# StarFive VisionFive 2 v1.3b register map
File version: 0.1
Registers are 32-bit, read-write, no defined reset value unless marked. A register's access mark holds for its fields unless they carry their own. Offsets are from the block's base; [hi:lo] are bit positions; {n}, {i} and the like mark numbered series; 'fields as' and 'values as' point back to an identical list.

## starfive_jh7110_syscrg_0 — From starfive,jh7110-syscrg, peripheral generator
Base 0x13020000
0x00 clk_cpu_root — Clock CPU Root
  [29:24] clk_mux_sel — Clock multiplexing selector: clk_osc, clk_pll0
0x04 clk_cpu_core — Clock CPU Core
  [23:0] clk_divcfg — Clock divider coefficient: Max=7, Default=1, Min=1, Typical=1
0x08 clk_cpu_bus — Clock CPU Bus
  [23:0] clk_divcfg — Clock divider coefficient: Max=2, Default=2, Min=2, Typical=2
0x0C clk_gpu_root — Clock GPU Root
  [29:24] clk_mux_sel — Clock multiplexing selector: clk_pll2, clk_pll1
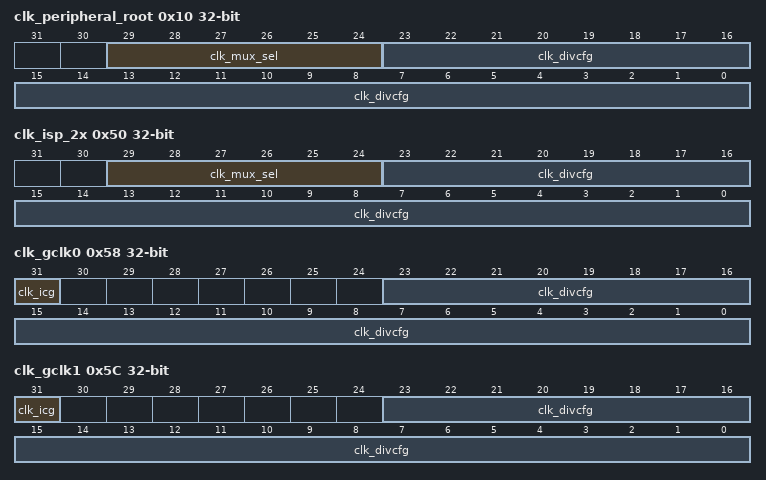
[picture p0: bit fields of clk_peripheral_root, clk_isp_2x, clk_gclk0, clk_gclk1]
0x10 clk_peripheral_root — Clock Peripheral Root
  [29:24] clk_mux_sel — Clock multiplexing selector: clk_pll0, clk_pll2
  [23:0] clk_divcfg — Clock divider coefficient: Max=2, Default=2, Min=2, Typical=2
0x14 clk_bus_root — Clock Bus Root
  [29:24] clk_mux_sel — Clock multiplexing selector: clk_osc, clk_pll2
0x18 clk_nocstg_bus — Clock NOCSTG Bus
  [23:0] clk_divcfg — Clock divider coefficient: Max=3, Default=3, Min=3, Typical=3
0x1C clk_axi_cfg0 — Clock AXI Configuration 0
  fields as clk_nocstg_bus
0x20 clk_stg_axiahb — Clock STG AXI AHB
  fields as clk_cpu_bus
0x24 clk_ahb0 — Clock AHB 0
  [31] clk_icg — 1: Clock enable, 0: Clock disable
0x28 clk_ahb1 — Clock AHB 1
  [31] clk_icg — 1: Clock enable, 0: Clock disable
0x2C clk_apb_bus — Clock APB Bus
  [23:0] clk_divcfg — Clock divider coefficient: Max=8, Default=4, Min=4, Typical=4
0x30 clk_apb0 — Clock APB 0
  [31] clk_icg — 1: Clock enable, 0: Clock disable
{0x34+4i} clk_pll{i}_div2 (i=0..2) — Clock PLL {i} Divider 2
  fields as clk_cpu_bus
0x40 clk_audio_root — Clock Audio Root
  [23:0] clk_divcfg — Clock divider coefficient: Max=8, Default=2, Min=2, Typical=2
0x44 clk_mclk_inner — Clock MCLK Inner
  [23:0] clk_divcfg — Clock divider coefficient: Max=64, Default=12, Min=12, Typical=12
0x48 clk_mclk — Clock MCLK
  [29:24] clk_mux_sel — Clock multiplexing selector: clk_mclk_inner, clk_mclk_ext
0x4C clk_mclk_out — Clock MCLK Out
  [31] clk_icg — 1: Clock enable, 0: Clock disable
0x50 clk_isp_2x — Clock ISP 2x
  [29:24] clk_mux_sel — Clock multiplexing selector: clk_pll2, clk_pll1
  [23:0] clk_divcfg — Clock divider coefficient: Max=8, Default=2, Min=2, Typical=2
0x54 clk_isp_axi — Clock ISP AXI
  [23:0] clk_divcfg — Clock divider coefficient: Max=4, Default=2, Min=2, Typical=2
0x58 clk_gclk0 — Clock GCLK 0
  [31] clk_icg — 1: Clock enable, 0: Clock disable
  [23:0] clk_divcfg — Clock divider coefficient: Max=62, Default=20, Min=16, Typical=20
0x5C clk_gclk1 — Clock GCLK 1
  [31] clk_icg — 1: Clock enable, 0: Clock disable
  [23:0] clk_divcfg — Clock divider coefficient: Max=62, Default=16, Min=16, Typical=16
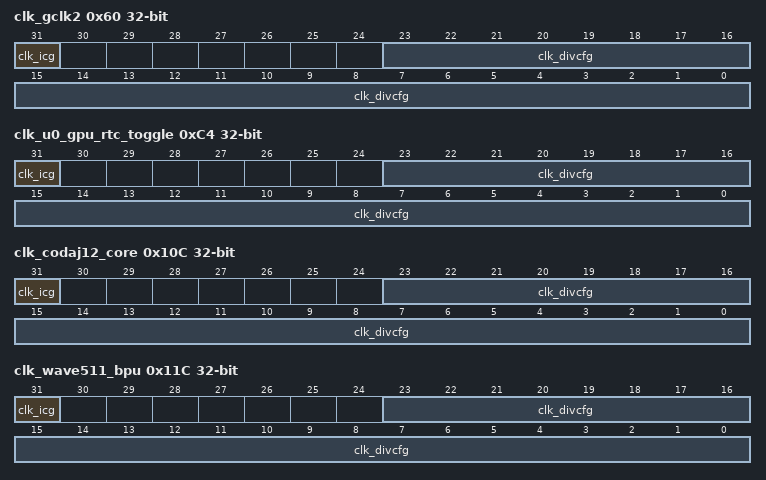
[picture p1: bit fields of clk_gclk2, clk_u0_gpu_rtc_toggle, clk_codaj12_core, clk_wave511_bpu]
0x60 clk_gclk2 — Clock GCLK 2
  [31] clk_icg — 1: Clock enable, 0: Clock disable
  [23:0] clk_divcfg — Clock divider coefficient: Max=62, Default=12, Min=12, Typical=12
{0x64+4i} clk_u7mc_core{i} (i=0..4) — U7MC Core Clock {i}
  [31] clk_icg — 1: Clock enable, 0: Clock disable
0x78 clk_u7mc_debug — U7MC Debug Clock
  [31] clk_icg — 1: Clock enable, 0: Clock disable
0x7C u7mc_rtc_toggle
  [23:0] clk_divcfg — Clock divider coefficient: Max=6, Default=6, Min=6, Typical=6
{0x80+4i} clk_u7mc_trace{i} (i=0..4) — U7MC Trace Clock {i}
  [31] clk_icg — 1: Clock enable, 0: Clock disable
0x94 clk_u7mc_trace_com — U7MC Trace Clock COM
  [31] clk_icg — 1: Clock enable, 0: Clock disable
0x98 clk_u0_sft7110_noc_bus_clk_cpu_axi
  [31] clk_icg — 1: Clock enable, 0: Clock disable
0x9C clk_u0_sft7110_noc_bus_clk_axicfg0_axi
  [31] clk_icg — 1: Clock enable, 0: Clock disable
0xA0 clk_osc_div2
  fields as clk_cpu_bus
0xA4 clk_pll1_div4
  fields as clk_cpu_bus
0xA8 clk_pll1_div8
  fields as clk_cpu_bus
0xAC clk_ddr_bus
  [29:24] clk_mux_sel — Clock multiplexing selector: clk_osc_div2, clk_pll1_div4, clk_pll1_div8
0xB0 clk_u0_ddr_sft7110_clk_axi — clk_u0_ddr_sfft7110_clk_axi
  [31] clk_icg — 1: Clock enable, 0: Clock disable
0xB4 clk_gpu_core
  [23:0] clk_divcfg — Clock divider coefficient: Max=7, Default=3, Min=3, Typical=3
0xB8 clk_u0_img_gpu_core_clk
  [31] clk_icg — 1: Clock enable, 0: Clock disable
0xBC clk_u0_img_gpu_sys_clk
  [31] clk_icg — 1: Clock enable, 0: Clock disable
0xC0 clk_u0_img_gpu_clk_apb
  [31] clk_icg — 1: Clock enable, 0: Clock disable
0xC4 clk_u0_gpu_rtc_toggle
  [31] clk_icg — 1: Clock enable, 0: Clock disable
  [23:0] clk_divcfg — Clock divider coefficient: Max=12, Default=12, Min=12, Typical=12
0xC8 clk_u0_sft7110_noc_bus_clk_gpu_axi
  [31] clk_icg — 1: Clock enable, 0: Clock disable
0xCC clk_u0_dom_isp_top_clk_dom_isp_top_clk_ispcore_2x
  [31] clk_icg — 1: Clock enable, 0: Clock disable
0xD0 clk_u0_dom_isp_top_clk_dom_isp_top_clk_isp_axi
  [31] clk_icg — 1: Clock enable, 0: Clock disable
0xD4 clk_u0_sft7110_noc_bux_clk_isp_axi
  [31] clk_icg — 1: Clock enable, 0: Clock disable
0xD8 clk_hifi4_core
  [23:0] clk_divcfg — Clock divider coefficient: Max=15, Default=3, Min=3, Typical=3
0xDC clk_hifi4_axi
  fields as clk_cpu_bus
0xE0 clk_u0_axi_cfg1_dec_clk_main
  [31] clk_icg — 1: Clock enable, 0: Clock disable
0xE4 clk_u0_axi_cfg1_dec_clk_ahb
  [31] clk_icg — 1: Clock enable, 0: Clock disable
0xE8 clk_u0_dom_vout_top_clk_dom_vout_top_clk_vout_src
  [31] clk_icg — 1: Clock enable, 0: Clock disable
0xEC clk_vout_axi_divcfg — Clock Video Output AXI DIVCFG
  [23:0] clk_divcfg — Clock divider coefficient: Max=7, Default=2, Min=2, Typical=2
0xF0 clk_noc_display_axi — Clock NOC Display AXI
  [31] clk_icg — 1: Clock enable, 0: Clock disable
0xF4 clk_vout_ahb — Clock Video Output AHB
  [31] clk_icg — 1: Clock enable, 0: Clock disable
0xF8 clk_vout_axi_icg — Clock Video Output AXI ICG
  [31] clk_icg — 1: Clock enable, 0: Clock disable
0xFC clk_vout_hdmi_tx0_mclk — Clock Video Output HDMI TX0 MCLK
  [31] clk_icg — 1: Clock enable, 0: Clock disable
0x100 clk_vout_mipi_phy — Clock Video Output MIPI PHY Reference
  fields as clk_cpu_bus
0x104 clk_jpeg_codec_axi — Clock JPEG Codec AXI
  [23:0] clk_divcfg — Clock divider coefficient: Max=16, Default=6, Min=6, Typical=6
0x108 clk_codaj12_axi — CODAJ12 Clock AXI
  [31] clk_icg — 1: Clock enable, 0: Clock disable
0x10C clk_codaj12_core — CODAJ12 Clock Core
  [31] clk_icg — 1: Clock enable, 0: Clock disable
  [23:0] clk_divcfg — Clock divider coefficient: Max=16, Default=6, Min=6, Typical=6
0x110 clk_codaj12_apb — CODAJ12 Clock APB
  [31] clk_icg — 1: Clock enable, 0: Clock disable
0x114 clk_vdec_axi — Clock Video Decoder AXI
  fields as clk_gpu_core
0x118 clk_wave511_axi — Clock WAVE511 AXI
  [31] clk_icg — 1: Clock enable, 0: Clock disable
0x11C clk_wave511_bpu — Clock WAVE511 BPU
  [31] clk_icg — 1: Clock enable, 0: Clock disable
  [23:0] clk_divcfg — Clock divider coefficient: Max=7, Default=3, Min=3, Typical=3
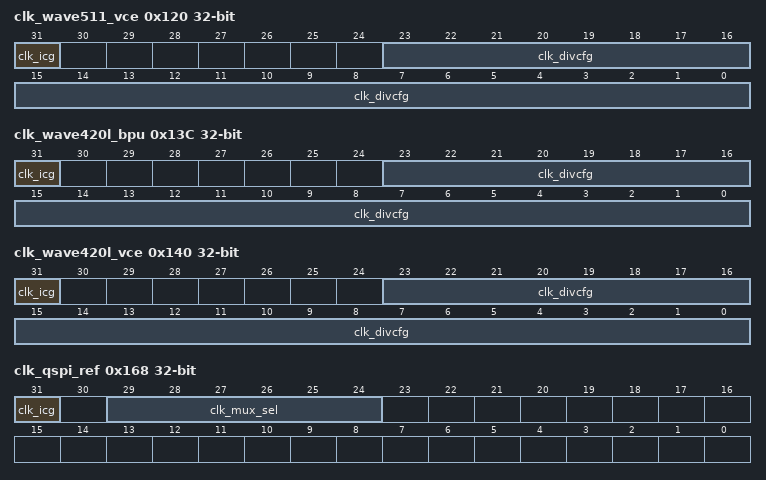
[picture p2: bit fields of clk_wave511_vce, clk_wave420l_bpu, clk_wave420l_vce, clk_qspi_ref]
0x120 clk_wave511_vce — Clock WAVE511 VCE
  [31] clk_icg — 1: Clock enable, 0: Clock disable
  [23:0] clk_divcfg — Clock divider coefficient: Max=7, Default=2, Min=3, Typical=2
0x124 clk_wave511_apb — Clock WAVE511 APB
  [31] clk_icg — 1: Clock enable, 0: Clock disable
0x128 clk_wave511_jpg_arb — Clock WAVE511 JPG ARB
  [31] clk_icg — 1: Clock enable, 0: Clock disable
0x12C clk_wave511_jpg_main — Clock WAVE511 JPG Main
  [31] clk_icg — 1: Clock enable, 0: Clock disable
0x130 clk_noc_vdec_axi — Clock NOC Video Decoder AXI
  [31] clk_icg — 1: Clock enable, 0: Clock disable
0x134 clk_venc_axi — Clock Video Encoder AXI
  [23:0] clk_divcfg — Clock divider coefficient: Max=15, Default=5, Min=5, Typical=5
0x138 clk_wave420l_axi — Clock WAVE420L AXI
  [31] clk_icg — 1: Clock enable, 0: Clock disable
0x13C clk_wave420l_bpu — Clock WAVE420L BPU
  [31] clk_icg — 1: Clock enable, 0: Clock disable
  [23:0] clk_divcfg — Clock divider coefficient: Max=15, Default=5, Min=5, Typical=5
0x140 clk_wave420l_vce — Clock WAVE420L VCE
  fields as clk_wave420l_bpu
0x144 clk_wave420l_apb — Clock WAVE420L APB
  [31] clk_icg — 1: Clock enable, 0: Clock disable
0x148 clk_noc_venc_axi — Clock NOC Video Encoder AXI
  [31] clk_icg — 1: Clock enable, 0: Clock disable
0x14C clk_axi_cfg0_dec_main_div — Clock AXI Config 0 DEC Main Divider
  [31] clk_icg — 1: Clock enable, 0: Clock disable
0x150 clk_axi_cfg0_dec_main — Clock AXI Config 0 DEC Main
  [31] clk_icg — 1: Clock enable, 0: Clock disable
0x154 clk_axi_cfg0_dec_hifi4 — Clock AXI Config 0 DEC HIFI4
  [31] clk_icg — 1: Clock enable, 0: Clock disable
0x158 clk_aximem_128b_axi — Clock AXIMEM 128B AXI
  [31] clk_icg — 1: Clock enable, 0: Clock disable
0x15C clk_qspi_ahb — Clock QSPI AHB
  [31] clk_icg — 1: Clock enable, 0: Clock disable
0x160 clk_qspi_apb — Clock QSPI APB
  [31] clk_icg — 1: Clock enable, 0: Clock disable
0x164 clk_qspi_ref_src — Clock QSPI Reference Source
  [23:0] clk_divcfg — Clock divider coefficient: Max=16, Default=10, Min=10, Typical=10
0x168 clk_qspi_ref — Clock QSPI Reference
  [31] clk_icg — 1: Clock enable, 0: Clock disable
  [29:24] clk_mux_sel — Clock multiplexing selector: clk_osc, clk_qspi_ref_src
0x16C clk_u0_sd_ahb — U0 SD Clock AHB
  [31] clk_icg — 1: Clock enable, 0: Clock disable
0x170 clk_u1_sd_ahb — U1 SD Clock AHB
  [31] clk_icg — 1: Clock enable, 0: Clock disable
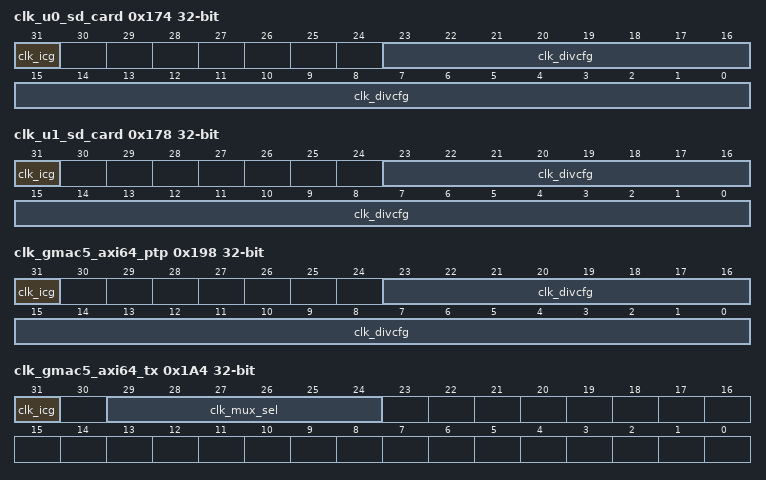
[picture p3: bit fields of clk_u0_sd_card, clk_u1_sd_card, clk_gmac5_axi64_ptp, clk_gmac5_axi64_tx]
0x174 clk_u0_sd_card — U0 SD Card Clock
  [31] clk_icg — 1: Clock enable, 0: Clock disable
  [23:0] clk_divcfg — Clock divider coefficient: Max=15, Default=2, Min=2, Typical=2
0x178 clk_u1_sd_card — U1 SD Card Clock
  fields as clk_u0_sd_card
0x17C clk_usb_125m — Clock USB 125M
  [23:0] clk_divcfg — Clock divider coefficient: Max=15, Default=8, Min=12, Typical=10
0x180 clk_noc_stg_axi — Clock NOC STG AXI
  [31] clk_icg — 1: Clock enable, 0: Clock disable
0x184 clk_gmac5_axi64_ahb — Clock GMAC 5 AXI 64 AHB
  [31] clk_icg — 1: Clock enable, 0: Clock disable
0x188 clk_gmac5_axi64_axi — Clock GMAC 5 AXI 64 AXI
  [31] clk_icg — 1: Clock enable, 0: Clock disable
0x18C clk_gmac_src — Clock GMAC Source
  fields as clk_vout_axi_divcfg
0x190 clk_gmac1_gtx — Clock GMAC 1 GTX
  fields as clk_usb_125m
0x194 clk_gmac1_rmii_rtx — Clock GMAC 1 RMII RTX
  [23:0] clk_divcfg — Clock divider coefficient: Max=30, Default=2, Min=2, Typical=2
0x198 clk_gmac5_axi64_ptp — Clock GMAC 5 AXI 64 PTP
  [31] clk_icg — 1: Clock enable, 0: Clock disable
  [23:0] clk_divcfg — Clock divider coefficient: Max=31, Default=10, Min=15, Typical=10
0x19C clk_gmac5_axi64_rx — Clock GMAC 5 AXI 64 RX
  [23:0] dly_chain_sel — Selector delay chain stage number, totally 32 stages, -50 ps each stage. The register value indicates the delay chain stage number. For example, diy_chain_sel=1 means to delay 1 stage.
0x1A0 clk_gmac5_axi64_rxi — Clock GMAC 5 AXI 64 RX Inverter
  [30] clk_polarity — 1: Clock inverter, 0: Clock buffer
0x1A4 clk_gmac5_axi64_tx — Clock GMAC 5 AXI 64 TX
  [31] clk_icg — 1: Clock enable, 0: Clock disable
  [29:24] clk_mux_sel — Clock multiplexing selector: clk_gmac1_gtxclk, clk_gmac1_rmii_rtx
0x1A8 clk_gmac5_axi64_txi — Clock GMAC 5 AXI 64 TX Inverter
  [30] clk_polarity — 1: Clock inverter, 0: Clock buffer
0x1AC clk_gmac1_gtxclk — Clock GMAC 1 GTXC
  fields as clk_gmac5_axi64_rx
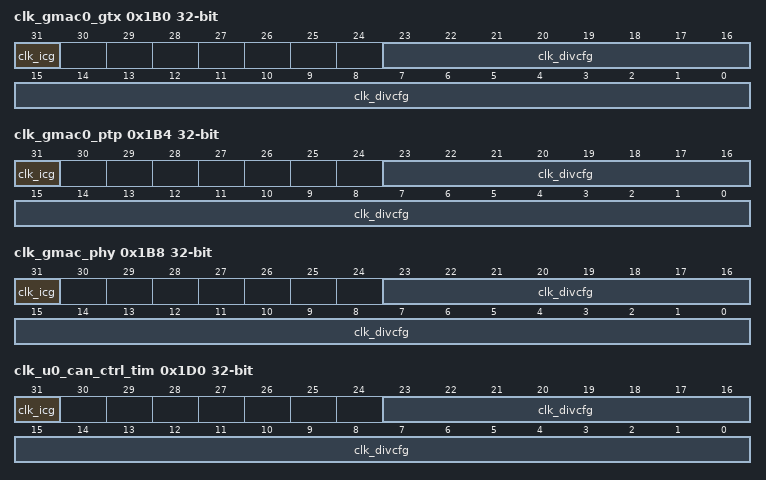
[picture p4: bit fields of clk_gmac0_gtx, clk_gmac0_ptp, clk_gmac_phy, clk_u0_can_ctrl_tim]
0x1B0 clk_gmac0_gtx — Clock GMAC 0 GTX
  [31] clk_icg — 1: Clock enable, 0: Clock disable
  [23:0] clk_divcfg — Clock divider coefficient: Max=15, Default=8, Min=12, Typical=10
0x1B4 clk_gmac0_ptp — Clock GMAC 0 PTP
  [31] clk_icg — 1: Clock enable, 0: Clock disable
  [23:0] clk_divcfg — Clock divider coefficient: Max=31, Default=10, Min=15, Typical=25
0x1B8 clk_gmac_phy — Clock GMAC PHY
  fields as clk_gmac0_ptp
0x1BC clk_gmac0_gtxclk — Clock GMAC 0 GTXC
  fields as clk_gmac5_axi64_rx
0x1C0 clk_sys_iomux_pclk — Clock SYS IOMUX PCLK
  [31] clk_icg — 1: Clock enable, 0: Clock disable
0x1C4 clk_mbox_apb — Clock Mailbox APB
  [31] clk_icg — 1: Clock enable, 0: Clock disable
0x1C8 clk_internal_ctrl_apb — Clock Internal Controller APB
  [31] clk_icg — 1: Clock enable, 0: Clock disable
0x1CC clk_u0_can_ctrl_apb — U0 Clock CAN Controller APB
  [31] clk_icg — 1: Clock enable, 0: Clock disable
0x1D0 clk_u0_can_ctrl_tim — U0 Clock CAN Controller Timer
  [31] clk_icg — 1: Clock enable, 0: Clock disable
  [23:0] clk_divcfg — Clock divider coefficient: Max=24, Default=24, Min=6, Typical=24
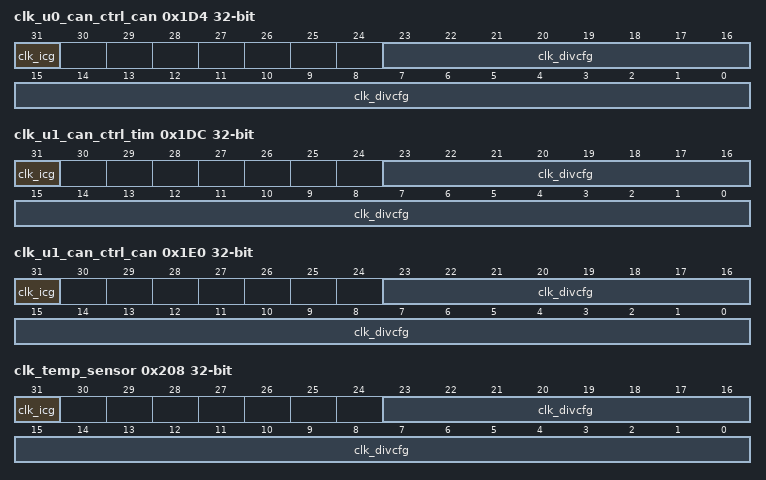
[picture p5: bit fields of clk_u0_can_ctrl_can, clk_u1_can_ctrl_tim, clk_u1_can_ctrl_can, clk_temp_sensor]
0x1D4 clk_u0_can_ctrl_can — U0 Clock CAN Controller CAN
  [31] clk_icg — 1: Clock enable, 0: Clock disable
  [23:0] clk_divcfg — Clock divider coefficient: Max=63, Default=8, Min=8, Typical=8
0x1D8 clk_u1_can_ctrl_apb — U1 Clock CAN Controller APB
  [31] clk_icg — 1: Clock enable, 0: Clock disable
0x1DC clk_u1_can_ctrl_tim — U1 Clock CAN Controller Timer
  fields as clk_u0_can_ctrl_tim
0x1E0 clk_u1_can_ctrl_can — U1 Clock CAN Controller CAN
  fields as clk_u0_can_ctrl_can
0x1E4 clk_pwm_apb — Clock PWM APB
  [31] clk_icg — 1: Clock enable, 0: Clock disable
0x1E8 clk_wdt_apb — Clock WDT APB
  [31] clk_icg — 1: Clock enable, 0: Clock disable
0x1EC clk_wdt — Clock WDT
  [31] clk_icg — 1: Clock enable, 0: Clock disable
0x1F0 clk_tim_apb — Clock Timer APB
  [31] clk_icg — 1: Clock enable, 0: Clock disable
{0x1F4+4i} clk_tim{i} (i=0..3) — Clock Timer {i}
  [31] clk_icg — 1: Clock enable, 0: Clock disable
0x204 clk_temp_sensor_apb — Clock Temperature Sensor APB
  [31] clk_icg — 1: Clock enable, 0: Clock disable
0x208 clk_temp_sensor — Clock Temperature Sensor
  [31] clk_icg — 1: Clock enable, 0: Clock disable
  [23:0] clk_divcfg — Clock divider coefficient: Max=24, Default=24, Min=24, Typical=24
{0x20C+4i} clk_u{i}_spi_apb (i=0..6) — U{i} Clock SPI APB
  [31] clk_icg — 1: Clock enable, 0: Clock disable
{0x228+4i} clk_u{i}_i2c_apb (i=0..6) — U{i} Clock I2C APB
  [31] clk_icg — 1: Clock enable, 0: Clock disable
{0x244+8i} clk_u{i}_uart_apb (i=0..5) — U{i} Clock UART APB
  [31] clk_icg — 1: Clock enable, 0: Clock disable
{0x248+8i} clk_u{i}_uart_core (i=0..2) — U{i} Clock UART Core
  [31] clk_icg — 1: Clock enable, 0: Clock disable
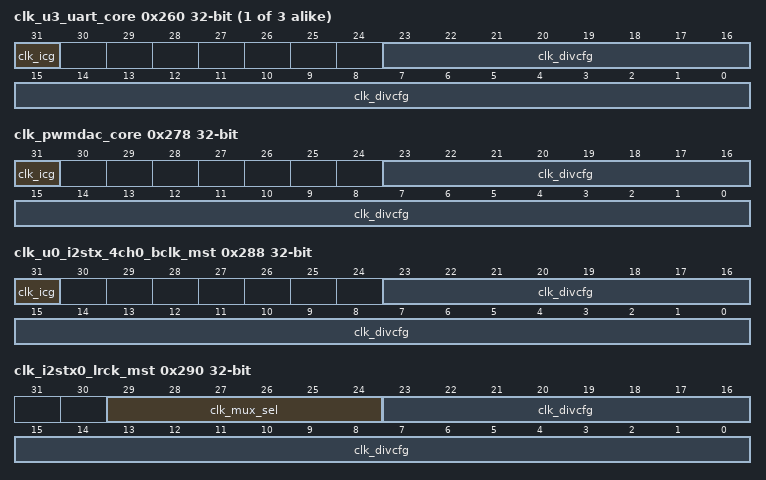
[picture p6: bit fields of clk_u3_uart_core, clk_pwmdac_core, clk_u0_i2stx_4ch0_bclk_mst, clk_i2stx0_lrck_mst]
{0x248+8i} clk_u{i}_uart_core (i=3..5) — U{i} Clock UART Core
  [31] clk_icg — 1: Clock enable, 0: Clock disable
  [23:0] clk_divcfg — Clock divider coefficient: Max=131071, Default=2560, Min=2560, Typical=2560
0x274 clk_pwmdac_apb — Clock PWMDAC APB
  [31] clk_icg — 1: Clock enable, 0: Clock disable
0x278 clk_pwmdac_core — Clock PWMDAC Core
  [31] clk_icg — 1: Clock enable, 0: Clock disable
  [23:0] clk_divcfg — Clock divider coefficient: Max=256, Default=12, Min=12, Typical=12
0x27C clk_spdif_apb — Clock SPDIF APB
  [31] clk_icg — 1: Clock enable, 0: Clock disable
0x280 clk_spdif_core — Clock SPDIF Core
  [31] clk_icg — 1: Clock enable, 0: Clock disable
0x284 clk_u0_i2s_tx_apb — U0 Clock I2S TX APB
  [31] clk_icg — 1: Clock enable, 0: Clock disable
0x288 clk_u0_i2stx_4ch0_bclk_mst — U0 Clock I2S TX 0 BCLK MST
  [31] clk_icg — 1: Clock enable, 0: Clock disable
  [23:0] clk_divcfg — Clock divider coefficient: Max=32, Default=4, Min=4, Typical=4
0x28C clk_u0_i2stx_4ch0_bclk_mst_inv — U0 Clock I2S TX 0 BCLK MST Inverter
  [30] clk_polarity — 1: Clock inverter, 0: Clock buffer
0x290 clk_i2stx0_lrck_mst — Clock I2S TX 0 LRCK MST
  [29:24] clk_mux_sel — Clock multiplexing selector: clk_i2stx_4ch0_bclk_mst_inv, clk_i2stx_4ch0_bclk_mst
  [23:0] clk_divcfg — Clock divider coefficient: Max=64, Default=64, Min=64, Typical=64
0x294 clk_u0_i2stx_bclk — U0 Clock I2S TX BCLK
  [29:24] clk_mux_sel — Clock multiplexing selector: clk_i2stx_4ch0_bclk_mst, clk_i2stx_bclk_ext
0x298 clk_u0_i2stx_bclk_neg — U0 Clock I2S TX BCLK Negative
  [30] clk_polarity — 1: Clock inverter, 0: Clock buffer
0x29C clk_u0_i2stx_lrck — U0 Clock I2S TX LRCK
  [29:24] clk_mux_sel — Clock multiplexing selector: clk_i2stx_4ch0_lrck_mst, clk_i2stx_lrck_ext
0x2A0 clk_u1_i2s_tx_apb — U1 Clock I2S TX APB
  [31] clk_icg — 1: Clock enable, 0: Clock disable
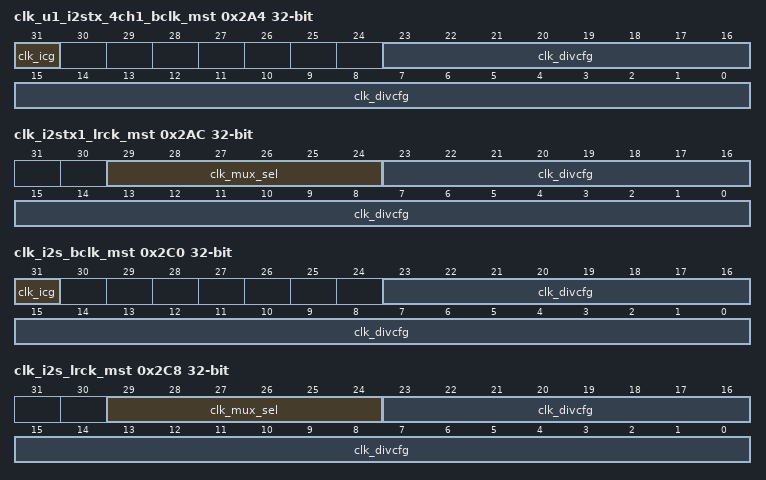
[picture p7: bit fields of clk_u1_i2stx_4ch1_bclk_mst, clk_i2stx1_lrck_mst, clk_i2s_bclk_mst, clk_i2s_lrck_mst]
0x2A4 clk_u1_i2stx_4ch1_bclk_mst — U1 Clock I2S TX 1 BCLK MST
  fields as clk_u0_i2stx_4ch0_bclk_mst
0x2A8 clk_u1_i2stx_4ch1_bclk_mst_inv — U1 Clock I2S TX 1 BCLK MST Inverter
  [30] clk_polarity — 1: Clock inverter, 0: Clock buffer
0x2AC clk_i2stx1_lrck_mst — Clock I2S TX 1 LRCK MST
  fields as clk_i2stx0_lrck_mst
0x2B0 clk_u1_i2stx_bclk — U1 Clock I2S TX BCLK
  [29:24] clk_mux_sel — Clock multiplexing selector: clk_i2stx_4ch1_bclk_mst, clk_i2stx_bclk_ext
0x2B4 clk_u1_i2stx_bclk_neg — U1 Clock I2S TX BCLK Negative
  [30] clk_polarity — 1: Clock inverter, 0: Clock buffer
0x2B8 clk_u1_i2stx_lrck — U1 Clock I2S TX LRCK
  [29:24] clk_mux_sel — Clock multiplexing selector: clk_i2stx_4ch1_lrck_mst, clk_i2stx_lrck_ext
0x2BC clk_i2s_apb — Clock I2S APB
  [31] clk_icg — 1: Clock enable, 0: Clock disable
0x2C0 clk_i2s_bclk_mst — Clock I2S BCLK MST
  fields as clk_u0_i2stx_4ch0_bclk_mst
0x2C4 clk_i2s_bclk_mst_inv — Clock I2S BCLK MST Inverter
  [30] clk_polarity — 1: Clock inverter, 0: Clock buffer
0x2C8 clk_i2s_lrck_mst — Clock I2S LRCK MST
  [29:24] clk_mux_sel — Clock multiplexing selector: clk_i2srx_3ch_bclk_mst_inv, clk_i2srx_3ch_bclk_mst
  [23:0] clk_divcfg — Clock divider coefficient: Max=64, Default=64, Min=64, Typical=64
0x2CC clk_i2s_bclk — Clock I2S BCLK
  [29:24] clk_mux_sel — Clock multiplexing selector: clk_i2srx_3ch_bclk_mst, clk_i2srx_3ch_bclk_ext
0x2D0 clk_i2s_bclk_neg — Clock I2S BCLK Negative
  [30] clk_polarity — 1: Clock inverter, 0: Clock buffer
0x2D4 clk_i2s_lrck — Clock I2S LRCK
  [29:24] clk_mux_sel — Clock multiplexing selector: clk_i2srx_3ch_lrck_mst, clk_i2srx_3ch_lrck_ext
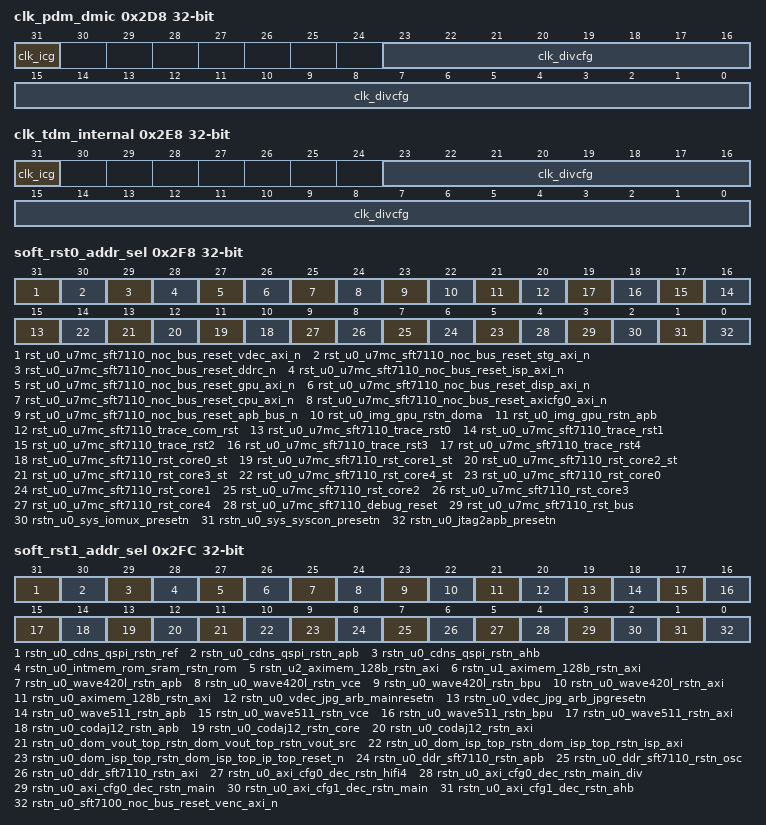
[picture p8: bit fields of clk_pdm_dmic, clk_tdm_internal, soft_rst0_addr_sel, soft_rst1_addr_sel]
0x2D8 clk_pdm_dmic — Clock PDM DMIC
  [31] clk_icg — 1: Clock enable, 0: Clock disable
  [23:0] clk_divcfg — Clock divider coefficient: Max=64, Default=8, Min=8, Typical=8
0x2DC clk_pdm_apb — Clock PDM APB
  [31] clk_icg — 1: Clock enable, 0: Clock disable
0x2E0 clk_tdm_ahb — Clock TDM AHB
  [31] clk_icg — 1: Clock enable, 0: Clock disable
0x2E4 clk_tdm_apb — Clock TDM APB
  [31] clk_icg — 1: Clock enable, 0: Clock disable
0x2E8 clk_tdm_internal — Clock TDM Internal
  [31] clk_icg — 1: Clock enable, 0: Clock disable
  [23:0] clk_divcfg — Clock divider coefficient: Max=64, Default=1, Min=1, Typical=1
0x2EC clk_tdm — Clock TDM
  [29:24] clk_mux_sel — Clock multiplexing selector: clk_tdm_internal, clk_tdm_ext
0x2F0 clk_tdm_neg — Clock TDM Negative
  [30] clk_polarity — 1: Clock inverter, 0: Clock buffer
0x2F4 clk_jtag_cert_trng — Clock JTAG Certification TRNG
  [23:0] clk_divcfg — Clock divider coefficient: Max=4, Default=4, Min=4, Typical=4
0x2F8 soft_rst0_addr_sel — Software RESET 0 Address Selector
  [31] rst_u0_u7mc_sft7110_noc_bus_reset_vdec_axi_n — 1: Assert reset, 0: De-assert reset
  [30] rst_u0_u7mc_sft7110_noc_bus_reset_stg_axi_n — 1: Assert reset, 0: De-assert reset
  [29] rst_u0_u7mc_sft7110_noc_bus_reset_ddrc_n — 1: Assert reset, 0: De-assert reset
  [28] rst_u0_u7mc_sft7110_noc_bus_reset_isp_axi_n — 1: Assert reset, 0: De-assert reset
  [27] rst_u0_u7mc_sft7110_noc_bus_reset_gpu_axi_n — 1: Assert reset, 0: De-assert reset
  [26] rst_u0_u7mc_sft7110_noc_bus_reset_disp_axi_n — 1: Assert reset, 0: De-assert reset
  [25] rst_u0_u7mc_sft7110_noc_bus_reset_cpu_axi_n — 1: Assert reset, 0: De-assert reset
  [24] rst_u0_u7mc_sft7110_noc_bus_reset_axicfg0_axi_n — 1: Assert reset, 0: De-assert reset
  [23] rst_u0_u7mc_sft7110_noc_bus_reset_apb_bus_n — 1: Assert reset, 0: De-assert reset
  [22] rst_u0_img_gpu_rstn_doma — 1: Assert reset, 0: De-assert reset
  [21] rst_u0_img_gpu_rstn_apb — 1: Assert reset, 0: De-assert reset
  [20] rst_u0_u7mc_sft7110_trace_com_rst — 1: Assert reset, 0: De-assert reset
  [n+15] rst_u0_u7mc_sft7110_trace_rst{n} (n=0..4) — 1: Assert reset, 0: De-assert reset
  [n+10] rst_u0_u7mc_sft7110_rst_core{n}_st (n=0..4) — 1: Assert reset, 0: De-assert reset
  [n+5] rst_u0_u7mc_sft7110_rst_core{n} (n=0..4) — 1: Assert reset, 0: De-assert reset
  [4] rst_u0_u7mc_sft7110_debug_reset — 1: Assert reset, 0: De-assert reset
  [3] rst_u0_u7mc_sft7110_rst_bus — 1: Assert reset, 0: De-assert reset
  [2] rstn_u0_sys_iomux_presetn — 1: Assert reset, 0: De-assert reset
  [1] rstn_u0_sys_syscon_presetn — 1: Assert reset, 0: De-assert reset
  [0] rstn_u0_jtag2apb_presetn — 1: Assert reset, 0: De-assert reset
0x2FC soft_rst1_addr_sel — Software RESET 1 Address Selector
  [31] rstn_u0_cdns_qspi_rstn_ref — 1: Assert reset, 0: De-assert reset
  [30] rstn_u0_cdns_qspi_rstn_apb — 1: Assert reset, 0: De-assert reset
  [29] rstn_u0_cdns_qspi_rstn_ahb — 1: Assert reset, 0: De-assert reset
  [28] rstn_u0_intmem_rom_sram_rstn_rom — 1: Assert reset, 0: De-assert reset
  [27] rstn_u2_aximem_128b_rstn_axi — 1: Assert reset, 0: De-assert reset
  [26] rstn_u1_aximem_128b_rstn_axi — 1: Assert reset, 0: De-assert reset
  [25] rstn_u0_wave420l_rstn_apb — 1: Assert reset, 0: De-assert reset
  [24] rstn_u0_wave420l_rstn_vce — 1: Assert reset, 0: De-assert reset
  [23] rstn_u0_wave420l_rstn_bpu — 1: Assert reset, 0: De-assert reset
  [22] rstn_u0_wave420l_rstn_axi — 1: Assert reset, 0: De-assert reset
  [21] rstn_u0_aximem_128b_rstn_axi — 1: Assert reset, 0: De-assert reset
  [20] rstn_u0_vdec_jpg_arb_mainresetn — 1: Assert reset, 0: De-assert reset
  [19] rstn_u0_vdec_jpg_arb_jpgresetn — 1: Assert reset, 0: De-assert reset
  [18] rstn_u0_wave511_rstn_apb — 1: Assert reset, 0: De-assert reset
  [17] rstn_u0_wave511_rstn_vce — 1: Assert reset, 0: De-assert reset
  [16] rstn_u0_wave511_rstn_bpu — 1: Assert reset, 0: De-assert reset
  [15] rstn_u0_wave511_rstn_axi — 1: Assert reset, 0: De-assert reset
  [14] rstn_u0_codaj12_rstn_apb — 1: Assert reset, 0: De-assert reset
  [13] rstn_u0_codaj12_rstn_core — 1: Assert reset, 0: De-assert reset
  [12] rstn_u0_codaj12_rstn_axi — 1: Assert reset, 0: De-assert reset
  [11] rstn_u0_dom_vout_top_rstn_dom_vout_top_rstn_vout_src — 1: Assert reset, 0: De-assert reset
  [10] rstn_u0_dom_isp_top_rstn_dom_isp_top_rstn_isp_axi — 1: Assert reset, 0: De-assert reset
  [9] rstn_u0_dom_isp_top_rstn_dom_isp_top_ip_top_reset_n — 1: Assert reset, 0: De-assert reset
  [8] rstn_u0_ddr_sft7110_rstn_apb — 1: Assert reset, 0: De-assert reset
  [7] rstn_u0_ddr_sft7110_rstn_osc — 1: Assert reset, 0: De-assert reset
  [6] rstn_u0_ddr_sft7110_rstn_axi — 1: Assert reset, 0: De-assert reset
  [5] rstn_u0_axi_cfg0_dec_rstn_hifi4 — 1: Assert reset, 0: De-assert reset
  [4] rstn_u0_axi_cfg0_dec_rstn_main_div — 1: Assert reset, 0: De-assert reset
  [3] rstn_u0_axi_cfg0_dec_rstn_main — 1: Assert reset, 0: De-assert reset
  [2] rstn_u0_axi_cfg1_dec_rstn_main — 1: Assert reset, 0: De-assert reset
  [1] rstn_u0_axi_cfg1_dec_rstn_ahb — 1: Assert reset, 0: De-assert reset
  [0] rstn_u0_sft7100_noc_bus_reset_venc_axi_n — 1: Assert reset, 0: De-assert reset
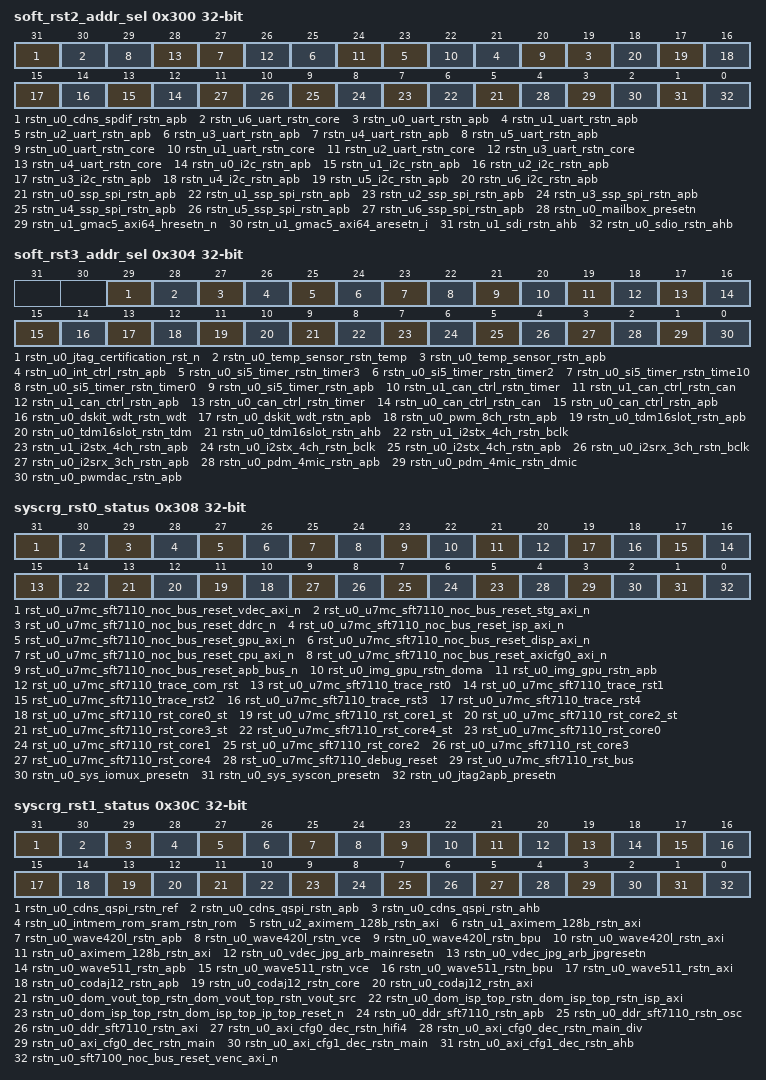
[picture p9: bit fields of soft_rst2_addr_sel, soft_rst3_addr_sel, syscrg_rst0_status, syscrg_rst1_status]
0x300 soft_rst2_addr_sel — Software RESET 2 Address Selector
  [31] rstn_u0_cdns_spdif_rstn_apb — 1: Assert reset, 0: De-assert reset
  [30] rstn_u6_uart_rstn_core — 1: Assert reset, 0: De-assert reset
  [2n+19] rstn_u{n}_uart_rstn_apb (n=0..5) — 1: Assert reset, 0: De-assert reset
  [2n+20] rstn_u{n}_uart_rstn_core (n=0..4) — 1: Assert reset, 0: De-assert reset
  [n+12] rstn_u{n}_i2c_rstn_apb (n=0..6) — 1: Assert reset, 0: De-assert reset
  [n+5] rstn_u{n}_ssp_spi_rstn_apb (n=0..6) — 1: Assert reset, 0: De-assert reset
  [4] rstn_u0_mailbox_presetn — 1: Assert reset, 0: De-assert reset
  [3] rstn_u1_gmac5_axi64_hresetn_n — 1: Assert reset, 0: De-assert reset
  [2] rstn_u1_gmac5_axi64_aresetn_i — 1: Assert reset, 0: De-assert reset
  [1] rstn_u1_sdi_rstn_ahb — 1: Assert reset, 0: De-assert reset
  [0] rstn_u0_sdio_rstn_ahb — 1: Assert reset, 0: De-assert reset
0x304 soft_rst3_addr_sel — Software RESET 3 Address Selector
  [29] rstn_u0_jtag_certification_rst_n — 1: Assert reset, 0: De-assert reset
  [28] rstn_u0_temp_sensor_rstn_temp — 1: Assert reset, 0: De-assert reset
  [27] rstn_u0_temp_sensor_rstn_apb — 1: Assert reset, 0: De-assert reset
  [26] rstn_u0_int_ctrl_rstn_apb — 1: Assert reset, 0: De-assert reset
  [25] rstn_u0_si5_timer_rstn_timer3 — 1: Assert reset, 0: De-assert reset
  [24] rstn_u0_si5_timer_rstn_timer2 — 1: Assert reset, 0: De-assert reset
  [23] rstn_u0_si5_timer_rstn_time10 — 1: Assert reset, 0: De-assert reset
  [22] rstn_u0_si5_timer_rstn_timer0 — 1: Assert reset, 0: De-assert reset
  [21] rstn_u0_si5_timer_rstn_apb — 1: Assert reset, 0: De-assert reset
  [20] rstn_u1_can_ctrl_rstn_timer — 1: Assert reset, 0: De-assert reset
  [19] rstn_u1_can_ctrl_rstn_can — 1: Assert reset, 0: De-assert reset
  [18] rstn_u1_can_ctrl_rstn_apb — 1: Assert reset, 0: De-assert reset
  [17] rstn_u0_can_ctrl_rstn_timer — 1: Assert reset, 0: De-assert reset
  [16] rstn_u0_can_ctrl_rstn_can — 1: Assert reset, 0: De-assert reset
  [15] rstn_u0_can_ctrl_rstn_apb — 1: Assert reset, 0: De-assert reset
  [14] rstn_u0_dskit_wdt_rstn_wdt — 1: Assert reset, 0: De-assert reset
  [13] rstn_u0_dskit_wdt_rstn_apb — 1: Assert reset, 0: De-assert reset
  [12] rstn_u0_pwm_8ch_rstn_apb — 1: Assert reset, 0: De-assert reset
  [11] rstn_u0_tdm16slot_rstn_apb — 1: Assert reset, 0: De-assert reset
  [10] rstn_u0_tdm16slot_rstn_tdm — 1: Assert reset, 0: De-assert reset
  [9] rstn_u0_tdm16slot_rstn_ahb — 1: Assert reset, 0: De-assert reset
  [8] rstn_u1_i2stx_4ch_rstn_bclk — 1: Assert reset, 0: De-assert reset
  [7] rstn_u1_i2stx_4ch_rstn_apb — 1: Assert reset, 0: De-assert reset
  [6] rstn_u0_i2stx_4ch_rstn_bclk — 1: Assert reset, 0: De-assert reset
  [5] rstn_u0_i2stx_4ch_rstn_apb — 1: Assert reset, 0: De-assert reset
  [4] rstn_u0_i2srx_3ch_rstn_bclk — 1: Assert reset, 0: De-assert reset
  [3] rstn_u0_i2srx_3ch_rstn_apb — 1: Assert reset, 0: De-assert reset
  [2] rstn_u0_pdm_4mic_rstn_apb — 1: Assert reset, 0: De-assert reset
  [1] rstn_u0_pdm_4mic_rstn_dmic — 1: Assert reset, 0: De-assert reset
  [0] rstn_u0_pwmdac_rstn_apb — 1: Assert reset, 0: De-assert reset
0x308 syscrg_rst0_status — SYSCRG RESET Status 0
  fields as soft_rst0_addr_sel
0x30C syscrg_rst1_status — SYSCRG RESET Status 1
  fields as soft_rst1_addr_sel
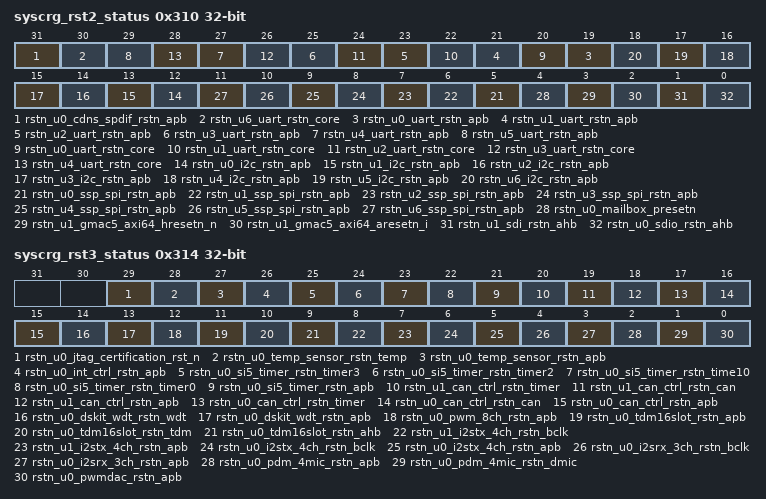
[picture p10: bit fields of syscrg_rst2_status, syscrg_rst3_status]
0x310 syscrg_rst2_status — SYSCRG RESET Status 2
  fields as soft_rst2_addr_sel
0x314 syscrg_rst3_status — SYSCRG RESET Status 3
  fields as soft_rst3_addr_sel
